# F28x7x_nmi_intrupt_regs register map
Vendor: Texas Instruments
Peripheral module from a debugger description file (folder C2000).
Address unit: 16 bits
Registers are 16-bit, read-write, no defined reset value unless marked. A register's access mark holds for its fields unless they carry their own. Offsets are as the file gives them; lines under a group give offsets from that group; [hi:lo] are bit positions; {n}, {i} and the like mark numbered series; 'fields as' and 'values as' point back to an identical list; <NAME> marks a mode.

## NMI_INTRUPT_REGS
0x00 NMICFG — NMI Configuration Register
  [0] NMIE — Global NMI Enable
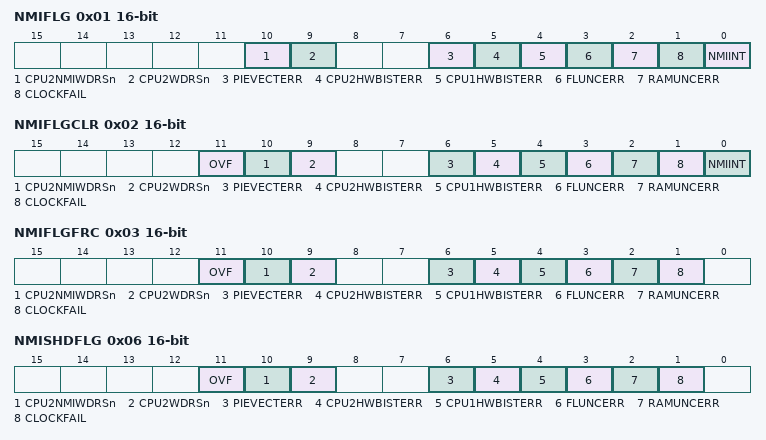
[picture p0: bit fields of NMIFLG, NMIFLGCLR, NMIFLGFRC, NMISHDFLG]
0x01 NMIFLG — NMI Flag Register (XRSn Clear)
  [10] CPU2NMIWDRSn — CPU2 NMIWDRSn Reset Indication Flag
  [9] CPU2WDRSn — CPU2 WDRSn Reset Indication Flag
  [6] PIEVECTERR — PIE Vector Fetch Error Flag
  [5] CPU2HWBISTERR — HW BIST Error NMI Flag
  [4] CPU1HWBISTERR — HW BIST Error NMI Flag
  [3] FLUNCERR — Flash Uncorrectable Error NMI Flag
  [2] RAMUNCERR — RAM Uncorrectable Error NMI Flag
  [1] CLOCKFAIL — Clock Fail Interrupt Flag
  [0] NMIINT — NMI Interrupt Flag
0x02 NMIFLGCLR — NMI Flag Clear Register
  [11] OVF — OVF Flag Clear
  [10] CPU2NMIWDRSn — CPU2NMIWDRSn Flag Clear
  [9] CPU2WDRSn — CPU2WDRSn Flag Clear
  [6] PIEVECTERR — PIEVECTERR Flag Clear
  [5] CPU2HWBISTERR — CPU2HWBISTERR Flag Clear
  [4] CPU1HWBISTERR — CPU1HWBISTERR Flag Clear
  [3] FLUNCERR — FLUNCERR Flag Clear
  [2] RAMUNCERR — RAMUNCERR Flag Clear
  [1] CLOCKFAIL — CLOCKFAIL Flag Clear
  [0] NMIINT — NMIINT Flag Clear
0x03 NMIFLGFRC — NMI Flag Force Register
  [11] OVF — OVF Flag Force
  [10] CPU2NMIWDRSn — CPU2NMIWDRSn Flag Force
  [9] CPU2WDRSn — CPU2WDRSn Flag Force
  [6] PIEVECTERR — PIEVECTERR Flag Force
  [5] CPU2HWBISTERR — CPU2HWBISTERR Flag Force
  [4] CPU1HWBISTERR — CPU1HWBISTERR Flag Force
  [3] FLUNCERR — FLUNCERR Flag Force
  [2] RAMUNCERR — RAMUNCERR Flag Force
  [1] CLOCKFAIL — CLOCKFAIL Flag Force
0x04 NMIWDCNT — NMI Watchdog Counter Register
  [15:0] NMIWDCNT — NMI Watchdog Counter
0x05 NMIWDPRD — NMI Watchdog Period Register
  [15:0] NMIWDPRD — NMI Watchdog Period
0x06 NMISHDFLG — NMI Shadow Flag Register
  [11] OVF — Shadow OVF Flag
  [10] CPU2NMIWDRSn — Shadow CPU2NMIWDRSn Flag
  [9] CPU2WDRSn — Shadow CPU2WDRSn Flag
  [6] PIEVECTERR — Shadow PIEVECTERR Flag
  [5] CPU2HWBISTERR — Shadow CPU2HWBISTERR Flag
  [4] CPU1HWBISTERR — Shadow CPU1HWBISTERR Flag
  [3] FLUNCERR — Shadow FLUNCERR Flag
  [2] RAMUNCERR — Shadow RAMUNCERR Flag
  [1] CLOCKFAIL — Shadow CLOCKFAIL Flag
